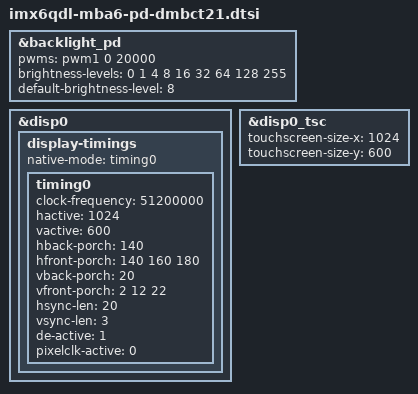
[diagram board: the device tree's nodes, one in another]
/*
 * Copyright 2014 Markus Niebel, TQ Systems GmbH
 *
 * The code contained herein is licensed under the GNU General Public
 * License. You may obtain a copy of the GNU General Public License
 * Version 2 or later at the following locations:
 *
 * http://www.opensource.org/licenses/gpl-license.html
 * http://www.gnu.org/copyleft/gpl.html
 */

#include "imx6qdl-mba6-pd.dtsi"

&backlight_pd {
	pwms = <&pwm1 0 20000>; /* 50 kHz */
	brightness-levels = <0 1 4 8 16 32 64 128 255>;
	default-brightness-level = <8>;
};

&disp0 {
	display-timings {
		/* S070WS12H-O-CT21 */
		native-mode = <&timing0>;
		timing0: timing0 {
			clock-frequency = <51200000>;
			hactive = <1024>;
			vactive = <600>;
			hback-porch = <140>;
			hfront-porch = <140 160 180>;
			vback-porch = <20>;
			vfront-porch = <2 12 22>;
			hsync-len = <20>;
			vsync-len = <3>;
			de-active = <1>;
			pixelclk-active = <0>;
		};
	};
};

&disp0_tsc {
	touchscreen-size-x = <1024>;
	touchscreen-size-y = <600>;
};

